# MSP432P401M register map
Vendor: Texas Instruments; File version: 3.230
Registers are 32-bit, read-write, reset 0x0 unless marked. A register's access mark holds for its fields unless they carry their own. Offsets are from the block's base; [hi:lo] are bit positions; {n}, {i} and the like mark numbered series.

## TLV
Base 0x00201000
0x00 TLV_CHECKSUM ro
0x04 DEVICE_INFO_TAG ro reset 0xB
0x08 DEVICE_INFO_LEN ro — Device Info Length
0x0C DEVICE_ID ro
0x10 HWREV ro — HW Revision
0x14 BCREV ro — Boot Code Revision
0x18 ROM_DRVLIB_REV ro — ROM Driver Library Revision
0x1C DIE_REC_TAG ro reset 0xC — Die Record Tag
0x20 DIE_REC_LEN ro — Die Record Length
0x24 DIE_XPOS ro — Die X-Position
0x28 DIE_YPOS ro — Die Y-Position
0x2C WAFER_ID ro
0x30 LOT_ID ro
0x40 TEST_RESULTS ro
0x44 CS_CAL_TAG ro reset 0x3 — Clock System Calibration Tag
0x48 CS_CAL_LEN ro — Clock System Calibration Length
0x4C DCOIR_FCAL_RSEL04 ro — DCO IR mode: Frequency calibration for DCORSEL 0 to 4
0x50 DCOIR_FCAL_RSEL5 ro — DCO IR mode: Frequency calibration for DCORSEL 5
0x64 DCOIR_CONSTK_RSEL04 ro — DCO IR mode: DCO Constant (K) for DCORSEL 0 to 4
0x68 DCOIR_CONSTK_RSEL5 ro — DCO IR mode: DCO Constant (K) for DCORSEL 5
0x6C DCOER_FCAL_RSEL04 ro — DCO ER mode: Frequency calibration for DCORSEL 0 to 4
0x70 DCOER_FCAL_RSEL5 ro — DCO ER mode: Frequency calibration for DCORSEL 5
0x84 DCOER_CONSTK_RSEL04 ro — DCO ER mode: DCO Constant (K) for DCORSEL 0 to 4
0x88 DCOER_CONSTK_RSEL5 ro — DCO ER mode: DCO Constant (K) for DCORSEL 5
0x8C ADC14_CAL_TAG ro reset 0x5 — ADC14 Calibration Tag
0x90 ADC14_CAL_LEN ro — ADC14 Calibration Length
0x94 ADC_GAIN_FACTOR ro
0x98 ADC_OFFSET ro
0xDC ADC14_REF1P2V_TS30C ro — ADC14 1.2V Reference Temp. Sensor 30C
0xE0 ADC14_REF1P2V_TS85C ro — ADC14 1.2V Reference Temp. Sensor 85C
0xE4 ADC14_REF1P45V_TS30C ro — ADC14 1.45V Reference Temp. Sensor 30C
0xE8 ADC14_REF1P45V_TS85C ro — ADC14 1.45V Reference Temp. Sensor 85C
0xEC ADC14_REF2P5V_TS30C ro — ADC14 2.5V Reference Temp. Sensor 30C
0xF0 ADC14_REF2P5V_TS85C ro — ADC14 2.5V Reference Temp. Sensor 85C
0xF4 REF_CAL_TAG ro reset 0x8 — REF Calibration Tag
0xF8 REF_CAL_LEN ro — REF Calibration Length
0xFC REF_1P2V ro — REF 1.2V Reference
0x100 REF_1P45V ro — REF 1.45V Reference
0x104 REF_2P5V ro — REF 2.5V Reference
0x108 FLASH_INFO_TAG ro reset 0x4
0x10C FLASH_INFO_LEN ro — Flash Info Length
0x110 FLASH_MAX_PROG_PULSES ro — Flash Maximum Programming Pulses
0x114 FLASH_MAX_ERASE_PULSES ro — Flash Maximum Erase Pulses
0x118 RANDOM_NUM_TAG ro reset 0xD — 128-bit Random Number Tag
0x11C RANDOM_NUM_LEN ro — 128-bit Random Number Length
{0x11C+4i} RANDOM_NUM_{i} ro (i=1..4) — 32-bit Random Number {i}
0x130 BSL_CFG_TAG ro reset 0xF — BSL Configuration Tag
0x134 BSL_CFG_LEN ro — BSL Configuration Length
0x138 BSL_PERIPHIF_SEL ro — BSL Peripheral Interface Selection
0x13C BSL_PORTIF_CFG_UART ro — BSL Port Interface Configuration for UART
0x140 BSL_PORTIF_CFG_SPI ro — BSL Port Interface Configuration for SPI
0x144 BSL_PORTIF_CFG_I2C ro — BSL Port Interface Configuration for I2C
0x148 TLV_END ro reset 0xBD0E11D — TLV End Word

## TIMER_A0
Base 0x40000000
Same registers: TIMER_A1 0x40000400, TIMER_A2 0x40000800, TIMER_A3 0x40000C00
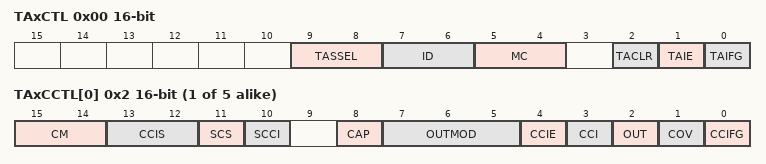
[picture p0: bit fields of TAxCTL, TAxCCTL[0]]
0x00 TAxCTL 16-bit — TimerAx Control Register
  [9:8] TASSEL — TimerA clock source select
    0=TAxCLK; 1=ACLK; 2=SMCLK; 3=INCLK
  [7:6] ID — Input divider
    0=/1; 1=/2; 2=/4; 3=/8
  [5:4] MC — Mode control
    0=Stop mode: Timer is halted; 1=Up mode: Timer counts up to TAxCCR0; 2=Continuous mode: Timer counts up to 0FFFFh; 3=Up/down mode: Timer counts up to TAxCCR0 then down to 0000h
  [2] TACLR — TimerA clear
  [1] TAIE — TimerA interrupt enable
    0=Interrupt disabled; 1=Interrupt enabled
  [0] TAIFG — TimerA interrupt flag
    0=No interrupt pending; 1=Interrupt pending
{0x2+2i} TAxCCTL[{i}] (i=0..4) 16-bit (reset mask 0xFFF7) — Timer_A Capture/Compare Control Register
  [15:14] CM — Capture mode
    0=No capture; 1=Capture on rising edge; 2=Capture on falling edge; 3=Capture on both rising and falling edges
  [13:12] CCIS — Capture/compare input select
    0=CCIxA; 1=CCIxB; 2=GND; 3=VCC
  [11] SCS — Synchronize capture source
    0=Asynchronous capture; 1=Synchronous capture
  [10] SCCI — Synchronized capture/compare input
  [8] CAP — Capture mode
    0=Compare mode; 1=Capture mode
  [7:5] OUTMOD — Output mode
    0=OUT bit value; 1=Set; 2=Toggle/reset; 3=Set/reset; 4=Toggle; 5=Reset; 6=Toggle/set; 7=Reset/set
  [4] CCIE — Capture/compare interrupt enable
    0=Interrupt disabled; 1=Interrupt enabled
  [3] CCI ro — Capture/compare input
  [2] OUT — Output
    0=Output low; 1=Output high
  [1] COV — Capture overflow
    0=No capture overflow occurred; 1=Capture overflow occurred
  [0] CCIFG — Capture/compare interrupt flag
    0=No interrupt pending; 1=Interrupt pending
0x10 TAxR 16-bit — TimerA register
{0x12+2i} TAxCCR[{i}] (i=0..4) 16-bit — Timer_A Capture/Compare Register
  [15:0] TAxR — TimerA register
0x20 TAxEX0 16-bit — TimerAx Expansion 0 Register
  [2:0] TAIDEX — Input divider expansion
    {v}=Divide by {v+1} (v=0..7)
0x2E TAxIV 16-bit ro — TimerAx Interrupt Vector Register
  [15:0] TAIV — TimerA interrupt vector value
    on read: 0=No interrupt pending; 2=Interrupt Source: Capture/compare 1; Interrupt Flag: TAxCCR1 CCIFG; Interrupt Priority: Highest; 4=Interrupt Source: Capture/compare 2; Interrupt Flag: TAxCCR2 CCIFG; 6=Interrupt Source: Capture/compare 3; Interrupt Flag: TAxCCR3 CCIFG; 8=Interrupt Source: Capture/compare 4; Interrupt Flag: TAxCCR4 CCIFG; 10=Interrupt Source: Capture/compare 5; Interrupt Flag: TAxCCR5 CCIFG; 12=Interrupt Source: Capture/compare 6; Interrupt Flag: TAxCCR6 CCIFG; 14=Interrupt Source: Timer overflow; Interrupt Flag: TAxCTL TAIFG; Interrupt Priority: Lowest

## Notices in the file
Copyright (C) 2012-2018 Texas Instruments Incorporated - http://www.ti.com
Redistribution and use in source and binary forms, with or without
modification, are permitted provided that the following conditions
are met:
Redistributions of source code must retain the above copyright
notice, this list of conditions and the following disclaimer.
Redistributions in binary form must reproduce the above copyright
notice, this list of conditions and the following disclaimer in the
documentation and/or other materials provided with the
distribution.
Neither the name of Texas Instruments Incorporated nor the names of
its contributors may be used to endorse or promote products derived
from this software without specific prior written permission.
THIS SOFTWARE IS PROVIDED BY THE COPYRIGHT HOLDERS AND CONTRIBUTORS
"AS IS" AND ANY EXPRESS OR IMPLIED WARRANTIES, INCLUDING, BUT NOT
LIMITED TO, THE IMPLIED WARRANTIES OF MERCHANTABILITY AND FITNESS FOR
A PARTICULAR PURPOSE ARE DISCLAIMED. IN NO EVENT SHALL THE COPYRIGHT
OWNER OR CONTRIBUTORS BE LIABLE FOR ANY DIRECT, INDIRECT, INCIDENTAL,
SPECIAL, EXEMPLARY, OR CONSEQUENTIAL DAMAGES (INCLUDING, BUT NOT
LIMITED TO, PROCUREMENT OF SUBSTITUTE GOODS OR SERVICES; LOSS OF USE,
DATA, OR PROFITS; OR BUSINESS INTERRUPTION) HOWEVER CAUSED AND ON ANY
THEORY OF LIABILITY, WHETHER IN CONTRACT, STRICT LIABILITY, OR TORT
(INCLUDING NEGLIGENCE OR OTHERWISE) ARISING IN ANY WAY OUT OF THE USE
OF THIS SOFTWARE, EVEN IF ADVISED OF THE POSSIBILITY OF SUCH DAMAGE.
